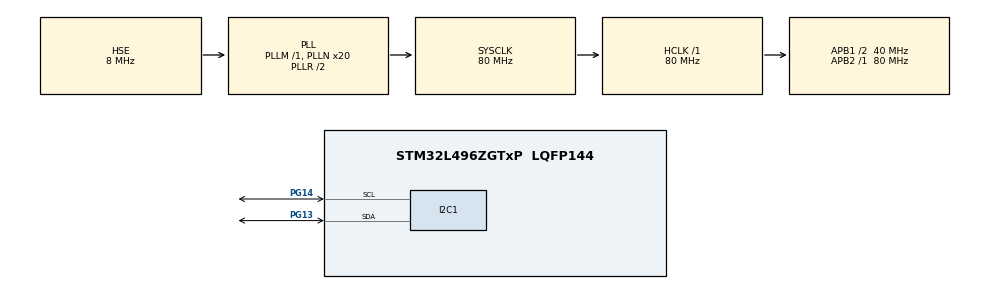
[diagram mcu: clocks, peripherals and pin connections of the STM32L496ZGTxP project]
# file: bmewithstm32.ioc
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I2C1.Timing=0x00D09BE3
Mcu.Family=STM32L4
Mcu.Name=STM32L496ZGTxP
Mcu.Package=LQFP144
NVIC.PriorityGroup=NVIC_PRIORITYGROUP_4
PA13\ (JTMS/SWDIO).Mode=Serial_Wire
PA13\ (JTMS/SWDIO).Signal=SYS_JTMS-SWDIO
PA14\ (JTCK/SWCLK).Mode=Serial_Wire
PA14\ (JTCK/SWCLK).Signal=SYS_JTCK-SWCLK
PG13.Mode=I2C
PG13.Signal=I2C1_SDA
PG14.Mode=I2C
PG14.Signal=I2C1_SCL
PH0-OSC_IN\ (PH0).Mode=HSE-External-Oscillator
PH0-OSC_IN\ (PH0).Signal=RCC_OSC_IN
PH1-OSC_OUT\ (PH1).Mode=HSE-External-Oscillator
PH1-OSC_OUT\ (PH1).Signal=RCC_OSC_OUT
ProjectManager.HeapSize=0x200
ProjectManager.StackSize=0x400
ProjectManager.TargetToolchain=STM32CubeIDE
RCC.48MHZClocksFreq_Value=24000000
RCC.ADCFreq_Value=80000000
RCC.AHBFreq_Value=80000000
RCC.APB1CLKDivider=RCC_HCLK_DIV2
RCC.APB1Freq_Value=40000000
RCC.APB1TimFreq_Value=80000000
RCC.APB2Freq_Value=80000000
RCC.APB2TimFreq_Value=80000000
RCC.CortexFreq_Value=80000000
RCC.HCLKFreq_Value=80000000
RCC.HSE_VALUE=8000000
RCC.HSI48_VALUE=48000000
RCC.HSI_VALUE=16000000
RCC.MSIClockRange=RCC_MSIRANGE_9
RCC.MSI_VALUE=24000000
RCC.PLLMUL=RCC_PLL_MUL9
RCC.PLLN=20
RCC.PLLSAI1N=20
RCC.PLLSourceVirtual=RCC_PLLSOURCE_HSE
RCC.PRESCALERUSB=RCC_USBCLKSOURCE_PLL_DIV1_5
RCC.SYSCLKFreq_VALUE=80000000
RCC.SYSCLKSource=RCC_SYSCLKSOURCE_PLLCLK
RCC.SYSCLKSourceVirtual=RCC_SYSCLKSOURCE_PLLCLK
RCC.USBFreq_Value=80000000
RCC.VCOOutputFreq_Value=160000000
board=NUCLEO-L496ZG-P

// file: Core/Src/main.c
/* USER CODE BEGIN Header */
/**
  ******************************************************************************
  * @file           : main.c
  * @brief          : Main program body
  ******************************************************************************
  * @attention
  *
  * Copyright (c) 2025 STMicroelectronics.
  * All rights reserved.
  *
  * This software is licensed under terms that can be found in the LICENSE file
  * in the root directory of this software component.
  * If no LICENSE file comes with this software, it is provided AS-IS.
  *
  ******************************************************************************
  */
/* USER CODE END Header */
#include "main.h"

/* USER CODE BEGIN Includes */
#include "BME280_STM32.h"

/* USER CODE END Includes */

I2C_HandleTypeDef hi2c1;

void SystemClock_Config(void);
static void MX_GPIO_Init(void);
static void MX_I2C1_Init(void);

/* USER CODE BEGIN 0 */

float Temperature, Pressure, Humidity;
/* USER CODE END 0 */

int main(void)
{
	float Temperature, Pressure, Humidity;

	int main(void)
	{
	  HAL_Init();

	  SystemClock_Config();

	  MX_GPIO_Init();
	  MX_I2C1_Init();

	  BME280_Config(OSRS_2, OSRS_16, OSRS_1, MODE_NORMAL, T_SB_0p5, IIR_16);

	  while (1)
	  {
		  BME280_Measure();
		  HAL_Delay (500);
	  }
	}

  /* MCU Configuration--------------------------------------------------------*/

  /* Reset of all peripherals, Initializes the Flash interface and the Systick. */
  HAL_Init();

  /* Configure the system clock */
  SystemClock_Config();

  /* Initialize all configured peripherals */
  MX_GPIO_Init();
  MX_I2C1_Init();
  /* USER CODE BEGIN 2 */

//BME280_Config(osrs_t, osrs_P, osrs_h, mode, t_sb, filter);
BME280_Config(OSRS_2, OSRS_16, OSRS_1, MODE_NORMAL, T_SB_0p5, IIR_16);

  /* USER CODE END 2 */

  /* Infinite loop */
  /* USER CODE BEGIN WHILE */
  while (1)
  {
	  BME280_Measure();
	  HAL_Delay(500);
//	  Temperature = bme280_data.temperature;
//	  Pressure = bme280_data.pressure;
//	  Humidity = bme280_data.humidity;

    /* USER CODE END WHILE */

  }
}

void SystemClock_Config(void)
{
  RCC_OscInitTypeDef RCC_OscInitStruct = {0};
  RCC_ClkInitTypeDef RCC_ClkInitStruct = {0};

  /** Configure the main internal regulator output voltage
  */
  if (HAL_PWREx_ControlVoltageScaling(PWR_REGULATOR_VOLTAGE_SCALE1) != HAL_OK)
  {
    Error_Handler();
  }

  /** Initializes the RCC Oscillators according to the specified parameters
  * in the RCC_OscInitTypeDef structure.
  */
  RCC_OscInitStruct.OscillatorType = RCC_OSCILLATORTYPE_HSE;
  RCC_OscInitStruct.HSEState = RCC_HSE_ON;
  RCC_OscInitStruct.PLL.PLLState = RCC_PLL_ON;
  RCC_OscInitStruct.PLL.PLLSource = RCC_PLLSOURCE_HSE;
  RCC_OscInitStruct.PLL.PLLM = 1;
  RCC_OscInitStruct.PLL.PLLN = 20;
  RCC_OscInitStruct.PLL.PLLP = RCC_PLLP_DIV2;
  RCC_OscInitStruct.PLL.PLLQ = RCC_PLLQ_DIV2;
  RCC_OscInitStruct.PLL.PLLR = RCC_PLLR_DIV2;
  if (HAL_RCC_OscConfig(&RCC_OscInitStruct) != HAL_OK)
  {
    Error_Handler();
  }

  /** Initializes the CPU, AHB and APB buses clocks
  */
  RCC_ClkInitStruct.ClockType = RCC_CLOCKTYPE_HCLK|RCC_CLOCKTYPE_SYSCLK
                              |RCC_CLOCKTYPE_PCLK1|RCC_CLOCKTYPE_PCLK2;
  RCC_ClkInitStruct.SYSCLKSource = RCC_SYSCLKSOURCE_PLLCLK;
  RCC_ClkInitStruct.AHBCLKDivider = RCC_SYSCLK_DIV1;
  RCC_ClkInitStruct.APB1CLKDivider = RCC_HCLK_DIV2;
  RCC_ClkInitStruct.APB2CLKDivider = RCC_HCLK_DIV1;

  if (HAL_RCC_ClockConfig(&RCC_ClkInitStruct, FLASH_LATENCY_4) != HAL_OK)
  {
    Error_Handler();
  }
}

static void MX_I2C1_Init(void)
{

  hi2c1.Instance = I2C1;
  hi2c1.Init.Timing = 0x00D09BE3;
  hi2c1.Init.OwnAddress1 = 0;
  hi2c1.Init.AddressingMode = I2C_ADDRESSINGMODE_7BIT;
  hi2c1.Init.DualAddressMode = I2C_DUALADDRESS_DISABLE;
  hi2c1.Init.OwnAddress2 = 0;
  hi2c1.Init.OwnAddress2Masks = I2C_OA2_NOMASK;
  hi2c1.Init.GeneralCallMode = I2C_GENERALCALL_DISABLE;
  hi2c1.Init.NoStretchMode = I2C_NOSTRETCH_DISABLE;
  if (HAL_I2C_Init(&hi2c1) != HAL_OK)
  {
    Error_Handler();
  }

  /** Configure Analogue filter
  */
  if (HAL_I2CEx_ConfigAnalogFilter(&hi2c1, I2C_ANALOGFILTER_ENABLE) != HAL_OK)
  {
    Error_Handler();
  }

  /** Configure Digital filter
  */
  if (HAL_I2CEx_ConfigDigitalFilter(&hi2c1, 0) != HAL_OK)
  {
    Error_Handler();
  }

}

static void MX_GPIO_Init(void)
{

  /* GPIO Ports Clock Enable */
  __HAL_RCC_GPIOH_CLK_ENABLE();
  __HAL_RCC_GPIOA_CLK_ENABLE();
  __HAL_RCC_GPIOG_CLK_ENABLE();
  HAL_PWREx_EnableVddIO2();

}

void Error_Handler(void)
{
  __disable_irq();
  while (1)
  {
  }
}
